# MEC1721N_B0_LJ register map
Vendor: Microchip Technology; Series: MEC172x; File version: 0
CPU: CM4 r1p0, little endian, MPU, FPU, 3 interrupt priority bits, 172 interrupts
Registers are 32-bit, read-write, reset 0x0 unless marked. A register's access mark holds for its fields unless they carry their own. Offsets are from the block's base; [hi:lo] are bit positions; {n}, {i} and the like mark numbered series.

## EMI0 — The EMI provides a communication between system host and Embedded Controller.
Base 0x400F4000; register names take the prefix EMI_
Same registers: EMI1 0x400F4400, EMI2 0x400F4800
0x00 RT_HOST2EC 8-bit — Host-to-EC Mailbox Register
0x01 RT_EC2HOST 8-bit — EC-to-Host Mailbox Register
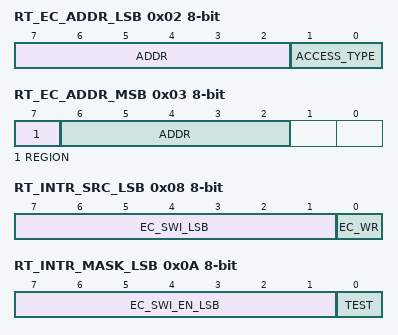
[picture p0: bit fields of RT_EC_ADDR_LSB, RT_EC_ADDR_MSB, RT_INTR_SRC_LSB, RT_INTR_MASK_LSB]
0x02 RT_EC_ADDR_LSB 8-bit — EC Address Access Control Register
  [7:2] ADDR — This field defines bits[7:2] of EC_Address [15:0]. Bits[1:0] of the EC_Address are always forced to 00b. The EC_Address is aligned on a DWord boundary. It is the address of the memory being accessed by EC Data Byte 0 Register, which is an offset from the programmed base address of the selected REGION.
  [1:0] ACCESS_TYPE — This field defines the type of access that occurs when the EC Data Register is read or written. 11b=Auto-increment 32-bit access. 10b=32-bit access. 01b=16-bit access. 00b=8-bit access.
0x03 RT_EC_ADDR_MSB 8-bit — EC Address Access Control Register
  [7] REGION — The field specifies which of two segments in the 32-bit internal address space is to be accessed by the EC_Address[14:2] to generate accesses to the memory. 1=The address defined by EC_Address[14:2] is relative to the base address specified by the Memory Base Address 1 Register. 0=The address defined by EC_Address[14:2] is relative to the base address specified by the Memory Base Address 0 Register.
  [6:2] ADDR — This field defines bits[14:8] of EC_Address. Bits[1:0] of the EC_Address are always forced to 00b. The EC_Address is aligned on a DWord boundary. It is the address of the memory being accessed by EC Data Byte 0 Register, which is an offset from the programmed base address of the selected REGION.
0x04 RT_DATA — EC Data Byte Register
0x08 RT_INTR_SRC_LSB 8-bit — Interrupt Source LSB Register
  [7:1] EC_SWI_LSB — EC Software Interrupt Least Significant Bits. These bits are software interrupt bits that may be set by the EC to notify the host of an event. The meaning of these bits is dependent on the firmware implementation. Each bit in this field is cleared when written with a '1b'. The ability to clear the bit can be disabled by the EC if the corresponding bit in the Host Clear Enable Register is set to '0b'. This may be used by firmware for events that cannot be cleared while the event is still active.
  [0] EC_WR — EC Mailbox Write. This bit is set when the EC-to-HOST Mailbox Register has been written by the EC at offset 01h of the EC-Only registers. Note: there is no corresponding mask bit in the Interrupt Mask LSB Register.
0x09 RT_INTR_SRC_MSB 8-bit — Interrupt Source MSB Register
  [7:0] EC_SWI_MSB — EC Software Interrupt Most Significant Bits. These bits are software interrupt bits that may be set by the EC to notify the host of an event. The meaning of these bits is dependent on the firmware implementation. Each bit in this field is cleared when written with a '1b'. The ability to clear the bit can be disabled by the EC if the corresponding bit in the Host Clear Enable Register is set to '0b'. This may be used by firmware for events that cannot be cleared while the event is still active.
0x0A RT_INTR_MASK_LSB 8-bit — Interrupt Mask LSB Register
  [7:1] EC_SWI_EN_LSB — EC Software Interrupt Enable Least Significant Bits. Each bit that is set to '1b' in this field enables the generation of a Host Event interrupt by the corresponding bit in the EC_SWI field in the Interrupt Source LSB Register.
  [0] TEST — Test Bit.
0x0B RT_INTR_MASK_MSB 8-bit — Interrupt Mask MSB Register
  [7:1] EC_SWI_EN_MSB — EC Software Interrupt Enable Most Significant Bits. Each bit that is set to '1b' in this field enables the generation of a Host Event interrupt by the corresponding bit in the EC_SWI field in the Interrupt Source MSB Register.
0x0C RT_APP_ID 8-bit — Application ID Register, APPLICATION_ID When this field is 00h it can be written with any value. When set to a non-zero value, writing that value will clear this register to 00h. When set to a non-zero value, writing any value other than the current contents will have no effect.
0x10 APP_ID_ASGN 8-bit — Application ID Assignment Register.
0x100 HOST2EC 8-bit — Host-to-EC Mailbox Register, 8-bit mailbox used communicate information from the system host to the embedded controller. Writing this register generates an event to notify the embedded controller. (R/WC)
0x101 EC2HOST 8-bit — EC-to-Host Mailbox Register, 8-bit mailbox used communicate information from the embedded controller to the system host. Writing this register generates an event to notify the system host.
0x104 MEM0_BASE — Memory Base Address 0 Register [31:2] This memory base address defines the beginning of region 0 in the Embedded Controller's 32-bit internal address space. Memory allocated to region 0 is intended to be shared between the Host and the EC. The region defined by this base register is used when bit 15 of the EC Address Register is 0. The access will be to a memory location at an offset defined by the EC_Address relative to the beginning of the region defined by this register. Therefore, a read or write to the memory that is triggered by the EC Data Register will occur at Memory_Base_Address_0 + EC_Address.
0x108 MEM0_RD_LIMITS 16-bit — Memory Read Limit 0 Register [14:2] Whenever a read of any byte in the EC Data Register is attempted, and bit 15 of EC_Address is 0, the field EC_Address[14:2] in the EC_Address_Register is compared to this field. As long as EC_Address[14:2] is less than this field the EC_Data_Register will be loaded from the 24-bit internal address space.
0x10A MEM0_WR_LIMITS 16-bit — Memory Write Limit 0 Register [14:2] Whenever a write of any byte in EC DATA Register is attempted and bit 15 of EC_Address is 0, the field EC_ADDRESS_MSB in the EC_Address Register is compared to this field. As long as EC_Address[14:2] is less than Memory_Write_Limit_0[14:2] the addressed bytes in the EC DATA Register will be written into the internal 24-bit address space. If EC_Address[14:2] is greater than or equal to the Memory_Write_Limit_0[14:2] no writes will take place.
0x10C MEM1_BASE — Memory Base Address 1 Register. [31:2] This memory base address defines the beginning of region 1 in the Embedded Controller's 32-bit internal address space. Memory allocated to region 1 is intended to be shared between the Host and the EC. The region defined by this base register is used when bit 15 of the EC Address Register is 1. The access will be to a memory location at an offset defined by the EC_Address relative to the beginning of the region defined by this register. Therefore, a read or write to the memory that is triggered by the EC Data Register will occur at Memory_Base_Address_1 + EC_Address.
0x110 MEM1_RD_LIMITS 16-bit — Memory Read Limit 1 Register, [14:2]: Whenever a read of any byte in the EC Data Register is attempted, and bit 15 of EC_ADDRESS is 1, the field EC_ADDRESS in the EC_Address_Register is compared to this field. As long as EC_ADDRESS is less than this value, the EC_Data_Register will be loaded from the 24-bit internal address space.
0x112 MEM1_WR_LIMITS 16-bit — Memory Write Limit 1 Register, [14:2]: Whenever a write of any byte in EC DATA Register is attempted and bit 15 of EC_Address is 1, the field EC_Address[14:2] in the EC_Address Register is compared to this field. As long as EC_Address[14:2] is less than Memory_Write_Limit_1[14:2] the addressed bytes in the EC DATA Register will be written into the internal 24-bit address space. If EC_Address[14:2] is greater than or equal to the Memory_Write_Limit_1[14:2] no writes will take place.
0x114 INTR_SET 16-bit — [15:1] Interrupt Set Register, Writing a bit in this field with a '1b' sets the corresponding bit in the Interrupt Source Register to '1b'. Writing a bit in this field with a '0b' has no effect. Reading this field returns the current contents of the Interrupt Source Register.
0x116 HOST_CLR_EN 16-bit — [15:1] Host Clear Enable Register, When a bit in this field is '0b', the corresponding bit in the Interrupt Source Register cannot be cleared by writes to the Interrupt Source Register. When a bit in this field is '1b', the corresponding bit in the Interrupt Source Register can be cleared when that register bit is written with a '1b'.
{0x120+4i} APP_ID_STS{i} (i=0..7) — Application ID Status register [{32i+31}:{32i}]
